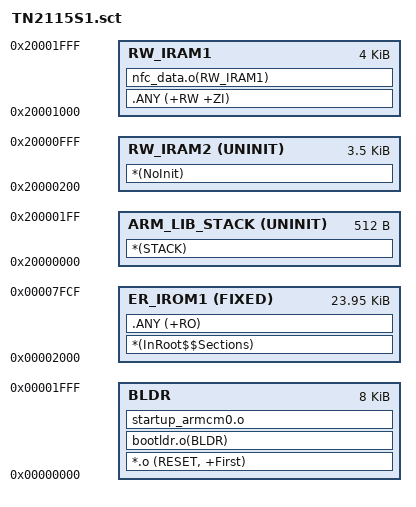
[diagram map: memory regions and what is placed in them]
; *************************************************************
; *** Scatter-Loading Description File generated by uVision ***
; *************************************************************

LR_IROM1 0x00000000 0x00008000  {    ; load region size_region
  BLDR 0x00000000 0x00002000  {  ; load address = execution address
   *.o (RESET, +First)
   bootldr.o(BLDR)
   startup_armcm0.o
  }
  ER_IROM1 0x00002000 FIXED 0x00005FD0 {  ; load address = execution address
   *(InRoot$$Sections)
   .ANY (+RO)
   
  }
  ARM_LIB_STACK 0x20000000 UNINIT 0x200  ; Stack region growing down
  { *(STACK) }

  RW_IRAM2 0x20000200 UNINIT 0x00000e00  {  ; no init data
   *(NoInit)
  }
  RW_IRAM1 0x20001000 0x00001000  {  ; RW data
   .ANY (+RW +ZI)
   nfc_data.o(RW_IRAM1)
  }
}

